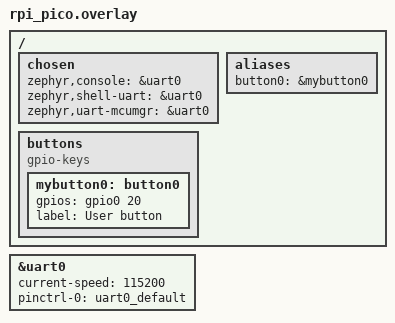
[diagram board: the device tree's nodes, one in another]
/ {
        chosen {
                zephyr,console = &uart0;
                zephyr,shell-uart = &uart0;
                zephyr,uart-mcumgr = &uart0;
        };
        
        aliases{
                button0 = &mybutton0;
        };


        buttons {
             compatible = "gpio-keys";
             mybutton0: button0 {
                     gpios = < &gpio0 20 GPIO_ACTIVE_HIGH>;
                     label = "User button";
             };
     };
};

uart0: &uart0 {
                status = "okay";
                current-speed = <115200>;
                pinctrl-0 = <&uart0_default>;
                pinctrl-names = "default";
};
